# MKW40Z4 register map
Vendor: Freescale Semiconductor, Inc.; Series: Kinetis_W; File version: 1.6
CPU: CM0PLUS r0p0, little endian, no MPU, no FPU, VTOR, 2 interrupt priority bits
Registers are 32-bit, read-write, reset 0x0 unless marked. A register's access mark holds for its fields unless they carry their own. Offsets are from the block's base; [hi:lo] are bit positions; {n}, {i} and the like mark numbered series.

## FTFA_FlashConfig — Flash configuration field
Base 0x00000400; register names take the prefix NV_
0x00 BACKKEY3 8-bit ro reset 0xFF — Backdoor Comparison Key 3.
  [7:0] KEY — Backdoor Comparison Key.
0x01 BACKKEY2 8-bit ro reset 0xFF — Backdoor Comparison Key 2.
  [7:0] KEY — Backdoor Comparison Key.
0x02 BACKKEY1 8-bit ro reset 0xFF — Backdoor Comparison Key 1.
  [7:0] KEY — Backdoor Comparison Key.
0x03 BACKKEY0 8-bit ro reset 0xFF — Backdoor Comparison Key 0.
  [7:0] KEY — Backdoor Comparison Key.
0x04 BACKKEY7 8-bit ro reset 0xFF — Backdoor Comparison Key 7.
  [7:0] KEY — Backdoor Comparison Key.
0x05 BACKKEY6 8-bit ro reset 0xFF — Backdoor Comparison Key 6.
  [7:0] KEY — Backdoor Comparison Key.
0x06 BACKKEY5 8-bit ro reset 0xFF — Backdoor Comparison Key 5.
  [7:0] KEY — Backdoor Comparison Key.
0x07 BACKKEY4 8-bit ro reset 0xFF — Backdoor Comparison Key 4.
  [7:0] KEY — Backdoor Comparison Key.
0x08 FPROT3 8-bit ro reset 0xFF — Non-volatile P-Flash Protection 1 - Low Register
  [7:0] PROT — P-Flash Region Protect
0x09 FPROT2 8-bit ro reset 0xFF — Non-volatile P-Flash Protection 1 - High Register
  [7:0] PROT — P-Flash Region Protect
0x0A FPROT1 8-bit ro reset 0xFF — Non-volatile P-Flash Protection 0 - Low Register
  [7:0] PROT — P-Flash Region Protect
0x0B FPROT0 8-bit ro reset 0xFF — Non-volatile P-Flash Protection 0 - High Register
  [7:0] PROT — P-Flash Region Protect
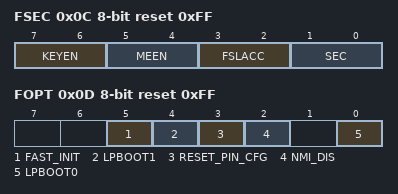
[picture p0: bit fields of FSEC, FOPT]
0x0C FSEC 8-bit ro reset 0xFF — Non-volatile Flash Security Register
  [7:6] KEYEN — Backdoor Key Security Enable
    2=Backdoor key access enabled; 3=Backdoor key access disabled
  [5:4] MEEN
    2=Mass erase is disabled; 3=Mass erase is enabled
  [3:2] FSLACC — Freescale Failure Analysis Access Code
    2=Freescale factory access denied; 3=Freescale factory access granted
  [1:0] SEC — Flash Security
    2=MCU security status is unsecure; 3=MCU security status is secure
0x0D FOPT 8-bit ro reset 0xFF — Non-volatile Flash Option Register
  [5] FAST_INIT
    0=Slower initialization; 1=Fast Initialization
  [4] LPBOOT1
    0=Core and system clock divider (OUTDIV1) is 0x7 (divide by 8) when LPBOOT0=0 or 0x3 (divide by 4) when LPBOOT0=1; 1=Core and system clock divider (OUTDIV1) is 0x1 (divide by 2) when LPBOOT0=0 or 0x0 (divide by 1) when LPBOOT0=1
  [3] RESET_PIN_CFG
    0=RESET pin is disabled following a POR and cannot be enabled as reset function; 1=RESET_b pin is dedicated
  [2] NMI_DIS
    0=NMI interrupts are always blocked; 1=NMI_b pin/interrupts reset default to enabled
  [0] LPBOOT0
    0=Core and system clock divider (OUTDIV1) is 0x7 (divide by 8) when LPBOOT1=0 or 0x1 (divide by 2) when LPBOOT1=1; 1=Core and system clock divider (OUTDIV1) is 0x3 (divide by 4) when LPBOOT1=0 or 0x0 (divide by 1) when LPBOOT1=1

## DMAMUX0 — DMA channel multiplexor
Base 0x40021000; register names take the prefix DMAMUX0_
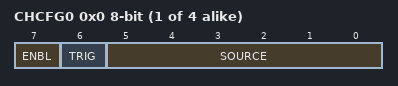
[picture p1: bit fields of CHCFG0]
{0x0+i} CHCFG{i} (i=0..3) 8-bit — Channel Configuration register
  [7] ENBL — DMA Channel Enable
    0=DMA channel is disabled. This mode is primarily used during configuration of the DMAMux. The DMA has separate channel enables/disables, which should be used to disable or reconfigure a DMA channel.; 1=DMA channel is enabled
  [6] TRIG — DMA Channel Trigger Enable
    0=Triggering is disabled. If triggering is disabled and ENBL is set, the DMA Channel will simply route the specified source to the DMA channel. (Normal mode); 1=Triggering is enabled. If triggering is enabled and ENBL is set, the DMAMUX is in Periodic Trigger mode.
  [5:0] SOURCE — DMA Channel Source (Slot)

## PIT — Periodic Interrupt Timer
Base 0x40037000; register names take the prefix PIT_
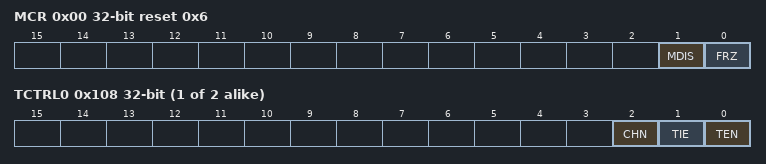
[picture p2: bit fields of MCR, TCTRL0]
0x00 MCR reset 0x6 — PIT Module Control Register
  [1] MDIS — Module Disable - (PIT section)
    0=Clock for standard PIT timers is enabled; 1=Clock for standard PIT timers is disabled
  [0] FRZ — Freeze
    0=Timers continue to run in Debug mode; 1=Timers are stopped in Debug mode
0xE0 LTMR64H ro — PIT Upper Lifetime Timer Register
  [31:0] LTH — Life Timer value
0xE4 LTMR64L ro — PIT Lower Lifetime Timer Register
  [31:0] LTL — Life Timer value
{0x100+0x10*i} LDVAL{i} (i=0..1) — Timer Load Value Register
  [31:0] TSV — Timer Start Value
{0x104+0x10*i} CVAL{i} (i=0..1) ro — Current Timer Value Register
  [31:0] TVL — Current Timer Value
{0x108+0x10*i} TCTRL{i} (i=0..1) — Timer Control Register
  [2] CHN — Chain Mode
    0=Timer is not chained; 1=Timer is chained to previous timer. For example, for Channel 2, if this field is set, Timer 2 is chained to Timer 1.
  [1] TIE — Timer Interrupt Enable
    0=Interrupt requests from Timer n are disabled; 1=Interrupt will be requested whenever TIF is set
  [0] TEN — Timer Enable
    0=Timer n is disabled; 1=Timer n is enabled
{0x10C+0x10*i} TFLG{i} (i=0..1) — Timer Flag Register
  [0] TIF — Timer Interrupt Flag
    0=Timeout has not yet occurred; 1=Timeout has occurred

## Notices in the file
Redistribution and use in source and binary forms, with or without modification,
are permitted provided that the following conditions are met:
o Redistributions of source code must retain the above copyright notice, this list
of conditions and the following disclaimer.
o Redistributions in binary form must reproduce the above copyright notice, this
list of conditions and the following disclaimer in the documentation and/or
other materials provided with the distribution.
o Neither the name of Freescale Semiconductor, Inc. nor the names of its
contributors may be used to endorse or promote products derived from this
software without specific prior written permission.
THIS SOFTWARE IS PROVIDED BY THE COPYRIGHT HOLDERS AND CONTRIBUTORS "AS IS" AND
ANY EXPRESS OR IMPLIED WARRANTIES, INCLUDING, BUT NOT LIMITED TO, THE IMPLIED
WARRANTIES OF MERCHANTABILITY AND FITNESS FOR A PARTICULAR PURPOSE ARE
DISCLAIMED. IN NO EVENT SHALL THE COPYRIGHT HOLDER OR CONTRIBUTORS BE LIABLE FOR
ANY DIRECT, INDIRECT, INCIDENTAL, SPECIAL, EXEMPLARY, OR CONSEQUENTIAL DAMAGES
(INCLUDING, BUT NOT LIMITED TO, PROCUREMENT OF SUBSTITUTE GOODS OR SERVICES;
LOSS OF USE, DATA, OR PROFITS; OR BUSINESS INTERRUPTION) HOWEVER CAUSED AND ON
ANY THEORY OF LIABILITY, WHETHER IN CONTRACT, STRICT LIABILITY, OR TORT
(INCLUDING NEGLIGENCE OR OTHERWISE) ARISING IN ANY WAY OUT OF THE USE OF THIS
SOFTWARE, EVEN IF ADVISED OF THE POSSIBILITY OF SUCH DAMAGE.
